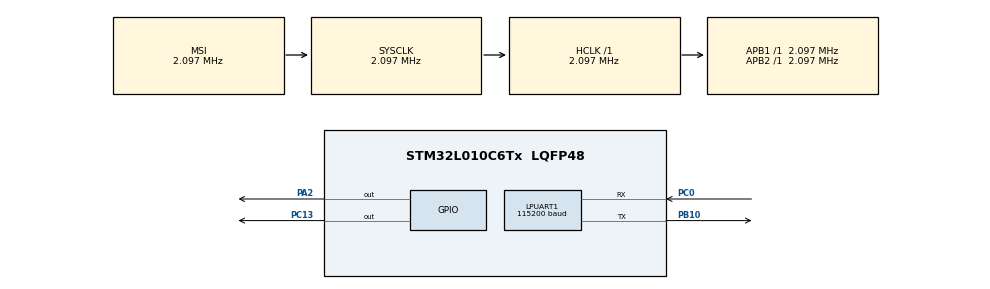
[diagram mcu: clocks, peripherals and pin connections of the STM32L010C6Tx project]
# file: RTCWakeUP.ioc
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LPUART1.BaudRate=115200
LPUART1.WordLength=UART_WORDLENGTH_8B
Mcu.Family=STM32L0
Mcu.Name=STM32L010C6Tx
Mcu.Package=LQFP48
NVIC.RTC_IRQn=true\:0\:0\:false\:false\:true\:true\:true
PA13.Mode=Serial_Wire
PA13.Signal=SYS_SWDIO
PA14.Mode=Serial_Wire
PA14.Signal=SYS_SWCLK
PA2.Signal=GPIO_Output
PB10.Mode=Asynchronous
PB10.Signal=LPUART1_TX
PC0.Mode=Asynchronous
PC0.Signal=LPUART1_RX
PC13-ANTI_TAMP.Signal=GPIO_Output
PH0-OSC_IN.Mode=HSE-External-Oscillator
PH0-OSC_IN.Signal=RCC_OSC_IN
PH1-OSC_OUT.Mode=HSE-External-Oscillator
PH1-OSC_OUT.Signal=RCC_OSC_OUT
ProjectManager.HeapSize=0x200
ProjectManager.StackSize=0x400
ProjectManager.TargetToolchain=STM32CubeIDE
RCC.AHBFreq_Value=2097000
RCC.APB1Freq_Value=2097000
RCC.APB1TimFreq_Value=2097000
RCC.APB2Freq_Value=2097000
RCC.APB2TimFreq_Value=2097000
RCC.HSE_VALUE=8000000
RCC.HSI16_VALUE=16000000
RCC.HSI_VALUE=16000000
RCC.LSE_VALUE=32768
RCC.MSI_VALUE=2097000
RCC.SYSCLKFreq_VALUE=2097000
RCC.VCOOutputFreq_Value=48000000
RTC.AsynchPrediv=124
RTC.SynchPrediv=295
VP_RTC_VS_RTC_Activate.Mode=RTC_Enabled
VP_RTC_VS_RTC_WakeUp_intern.Mode=WakeUp
board=custom

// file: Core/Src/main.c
/* USER CODE BEGIN Header */
/**
  ******************************************************************************
  * @file           : main.c
  * @brief          : Main program body
  ******************************************************************************
  * @attention
  *
  * <h2><center>&copy; Copyright (c) 2022 STMicroelectronics.
  * All rights reserved.</center></h2>
  *
  * This software component is licensed by ST under BSD 3-Clause license,
  * the "License"; You may not use this file except in compliance with the
  * License. You may obtain a copy of the License at:
  *                        opensource.org/licenses/BSD-3-Clause
  *
  ******************************************************************************
  */
/* USER CODE END Header */
#include "main.h"

UART_HandleTypeDef hlpuart1;

RTC_HandleTypeDef hrtc;

void SystemClock_Config(void);
static void MX_GPIO_Init(void);
static void MX_LPUART1_UART_Init(void);
static void MX_RTC_Init(void);

int main(void)
{

  /* MCU Configuration--------------------------------------------------------*/

  /* Reset of all peripherals, Initializes the Flash interface and the Systick. */
  HAL_Init();

  /* Configure the system clock */
  SystemClock_Config();

  /* Initialize all configured peripherals */
  MX_GPIO_Init();
  MX_LPUART1_UART_Init();
  MX_RTC_Init();

  /* Infinite loop */
  while (1)
  {

    /* USER CODE BEGIN 3 */
	  //https://community.st.com/s/article/how-to-configure-the-rtc-to-wake-up-the-stm32-periodically-from-low-power-modes
	  //https://www.st.com/resource/en/application_note/an4445-stm32l0xx-ultralow-power-features-overview-stmicroelectronics.pdf
	  HAL_GPIO_WritePin(GPIOC, GPIO_PIN_13, GPIO_PIN_SET);
      HAL_UART_Transmit(&hlpuart1, "yandi\r\n", 7, 1000);

      HAL_Delay(3000);

	  HAL_GPIO_WritePin(GPIOC, GPIO_PIN_13, GPIO_PIN_RESET);
      HAL_UART_Transmit(&hlpuart1, "sondu\r\n", 7, 1000);
	  HAL_SuspendTick();
	  HAL_RTCEx_SetWakeUpTimer_IT(&hrtc, 0x5A55, RTC_WAKEUPCLOCK_RTCCLK_DIV16);

	//HAL_PWREx_EnterSTOPMode(PWR_STOPENTRY_WFI);
	    HAL_PWR_EnterSTOPMode(PWR_LOWPOWERREGULATOR_ON, PWR_STOPENTRY_WFE);
	  HAL_RTCEx_DeactivateWakeUpTimer(&hrtc);
	  SystemClock_Config();
	  HAL_ResumeTick();

	   }
  /* USER CODE END 3 */
}

void SystemClock_Config(void)
{
  RCC_OscInitTypeDef RCC_OscInitStruct = {0};
  RCC_ClkInitTypeDef RCC_ClkInitStruct = {0};
  RCC_PeriphCLKInitTypeDef PeriphClkInit = {0};

  /** Configure the main internal regulator output voltage
  */
  __HAL_PWR_VOLTAGESCALING_CONFIG(PWR_REGULATOR_VOLTAGE_SCALE1);
  /** Initializes the RCC Oscillators according to the specified parameters
  * in the RCC_OscInitTypeDef structure.
  */
  RCC_OscInitStruct.OscillatorType = RCC_OSCILLATORTYPE_LSI|RCC_OSCILLATORTYPE_MSI;
  RCC_OscInitStruct.LSIState = RCC_LSI_ON;
  RCC_OscInitStruct.MSIState = RCC_MSI_ON;
  RCC_OscInitStruct.MSICalibrationValue = 0;
  RCC_OscInitStruct.MSIClockRange = RCC_MSIRANGE_5;
  RCC_OscInitStruct.PLL.PLLState = RCC_PLL_NONE;
  if (HAL_RCC_OscConfig(&RCC_OscInitStruct) != HAL_OK)
  {
    Error_Handler();
  }
  /** Initializes the CPU, AHB and APB buses clocks
  */
  RCC_ClkInitStruct.ClockType = RCC_CLOCKTYPE_HCLK|RCC_CLOCKTYPE_SYSCLK
                              |RCC_CLOCKTYPE_PCLK1|RCC_CLOCKTYPE_PCLK2;
  RCC_ClkInitStruct.SYSCLKSource = RCC_SYSCLKSOURCE_MSI;
  RCC_ClkInitStruct.AHBCLKDivider = RCC_SYSCLK_DIV1;
  RCC_ClkInitStruct.APB1CLKDivider = RCC_HCLK_DIV1;
  RCC_ClkInitStruct.APB2CLKDivider = RCC_HCLK_DIV1;

  if (HAL_RCC_ClockConfig(&RCC_ClkInitStruct, FLASH_LATENCY_0) != HAL_OK)
  {
    Error_Handler();
  }
  PeriphClkInit.PeriphClockSelection = RCC_PERIPHCLK_LPUART1|RCC_PERIPHCLK_RTC;
  PeriphClkInit.Lpuart1ClockSelection = RCC_LPUART1CLKSOURCE_PCLK1;
  PeriphClkInit.RTCClockSelection = RCC_RTCCLKSOURCE_LSI;
  if (HAL_RCCEx_PeriphCLKConfig(&PeriphClkInit) != HAL_OK)
  {
    Error_Handler();
  }
}

static void MX_LPUART1_UART_Init(void)
{

  hlpuart1.Instance = LPUART1;
  hlpuart1.Init.BaudRate = 115200;
  hlpuart1.Init.WordLength = UART_WORDLENGTH_8B;
  hlpuart1.Init.StopBits = UART_STOPBITS_1;
  hlpuart1.Init.Parity = UART_PARITY_NONE;
  hlpuart1.Init.Mode = UART_MODE_TX_RX;
  hlpuart1.Init.HwFlowCtl = UART_HWCONTROL_NONE;
  hlpuart1.Init.OneBitSampling = UART_ONE_BIT_SAMPLE_DISABLE;
  hlpuart1.AdvancedInit.AdvFeatureInit = UART_ADVFEATURE_NO_INIT;
  if (HAL_UART_Init(&hlpuart1) != HAL_OK)
  {
    Error_Handler();
  }

}

static void MX_RTC_Init(void)
{

  /** Initialize RTC Only
  */
  hrtc.Instance = RTC;
  hrtc.Init.HourFormat = RTC_HOURFORMAT_24;
  hrtc.Init.AsynchPrediv = 124;
  hrtc.Init.SynchPrediv = 295;
  hrtc.Init.OutPut = RTC_OUTPUT_DISABLE;
  hrtc.Init.OutPutRemap = RTC_OUTPUT_REMAP_NONE;
  hrtc.Init.OutPutPolarity = RTC_OUTPUT_POLARITY_HIGH;
  hrtc.Init.OutPutType = RTC_OUTPUT_TYPE_OPENDRAIN;
  if (HAL_RTC_Init(&hrtc) != HAL_OK)
  {
    Error_Handler();
  }
  /** Enable the WakeUp
  */
  if (HAL_RTCEx_SetWakeUpTimer_IT(&hrtc, 0, RTC_WAKEUPCLOCK_RTCCLK_DIV16) != HAL_OK)
  {
    Error_Handler();
  }

}

static void MX_GPIO_Init(void)
{
  GPIO_InitTypeDef GPIO_InitStruct = {0};

  /* GPIO Ports Clock Enable */
  __HAL_RCC_GPIOC_CLK_ENABLE();
  __HAL_RCC_GPIOH_CLK_ENABLE();
  __HAL_RCC_GPIOA_CLK_ENABLE();
  __HAL_RCC_GPIOB_CLK_ENABLE();

  /*Configure GPIO pin Output Level */
  HAL_GPIO_WritePin(GPIOC, GPIO_PIN_13, GPIO_PIN_RESET);

  /*Configure GPIO pin Output Level */
  HAL_GPIO_WritePin(GPIOA, GPIO_PIN_2, GPIO_PIN_RESET);

  /*Configure GPIO pin : PC13 */
  GPIO_InitStruct.Pin = GPIO_PIN_13;
  GPIO_InitStruct.Mode = GPIO_MODE_OUTPUT_PP;
  GPIO_InitStruct.Pull = GPIO_NOPULL;
  GPIO_InitStruct.Speed = GPIO_SPEED_FREQ_LOW;
  HAL_GPIO_Init(GPIOC, &GPIO_InitStruct);

  /*Configure GPIO pin : PA2 */
  GPIO_InitStruct.Pin = GPIO_PIN_2;
  GPIO_InitStruct.Mode = GPIO_MODE_OUTPUT_PP;
  GPIO_InitStruct.Pull = GPIO_NOPULL;
  GPIO_InitStruct.Speed = GPIO_SPEED_FREQ_LOW;
  HAL_GPIO_Init(GPIOA, &GPIO_InitStruct);

}

void Error_Handler(void)
{
  __disable_irq();
  while (1)
  {
  }
}

/************************ (C) COPYRIGHT STMicroelectronics *****END OF FILE****/
